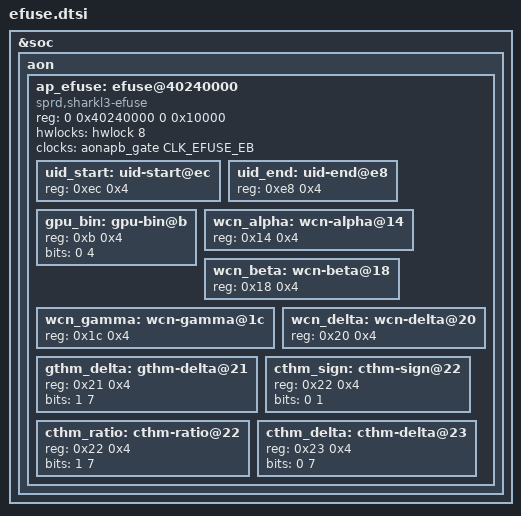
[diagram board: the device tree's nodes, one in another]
// SPDX-License-Identifier: (GPL-2.0+ OR MIT)
/*
 * Unisoc efuse dts file
 *
 * Copyright (C) 2023, Unisoc Inc.
 *
 */

&soc {
	aon: aon {
		ap_efuse: efuse@40240000 {
			compatible = "sprd,sharkl3-efuse";
			reg = <0 0x40240000 0 0x10000>;
			#address-cells = <1>;
			#size-cells = <1>;
			clock-names = "enable";
			hwlocks = <&hwlock 8>;
			clocks = <&aonapb_gate CLK_EFUSE_EB>;

			uid_start: uid-start@ec{
				reg = <0xec 0x4>;
			};

			uid_end: uid-end@e8{
				reg = <0xe8 0x4>;
			};

			gpu_bin: gpu-bin@b {
				reg = <0xb 0x4>;
				bits = <0 4>;
			};

			wcn_alpha: wcn-alpha@14 {
				reg = <0x14 0x4>;
			};

			wcn_beta: wcn-beta@18 {
				reg = <0x18 0x4>;
			};

			wcn_gamma: wcn-gamma@1c {
				reg = <0x1c 0x4>;
			};

			wcn_delta: wcn-delta@20 {
				reg = <0x20 0x4>;
			};

			gthm_delta: gthm-delta@21{
				reg = <0x21 0x4>;
				bits = <1 7>;
			};

			cthm_sign: cthm-sign@22{
				reg = <0x22 0x4>;
				bits = <0 1>;
			};

			cthm_ratio: cthm-ratio@22{
				reg = <0x22 0x4>;
				bits = <1 7>;
			};

			cthm_delta: cthm-delta@23{
				reg = <0x23 0x4>;
				bits = <0 7>;
			};
		};
	};
};
